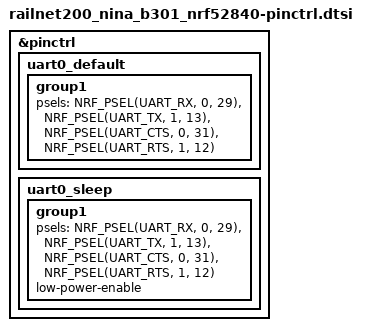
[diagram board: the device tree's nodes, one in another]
/*
 * Copyright (c) 2025 Naonext
 * SPDX-License-Identifier: Apache-2.0
 */

/*
 * NINA-B301 pin mapping on Railnet200 board (u-blox NINA-B301-00B, U22)
 *
 * The NINA-B301 is wired directly to the iMX6 CPU via its module pins.
 * UART0 of the nRF52840 inside NINA-B301 is used for HCI transport.
 *
 * NINA-B301 module pin -> nRF52840 GPIO -> signal name (Railnet200 net)
 *   Pin 23 (GPIO_23 / P0.29) -> UART_RX  -> BLE_UART_TX  (iMX6 TX → NINA RXD)
 *   Pin 22 (GPIO_22 / P1.13) -> UART_TX  -> BLE_UART_RX  (iMX6 RX ← NINA TXD)
 *   Pin 20 (GPIO_20 / P0.31) -> UART_CTS <- BLE_UART_CTS (iMX6 ball55 DCE_CTS out → NINA CTS in)
 *   Pin 21 (GPIO_21 / P1.12) -> UART_RTS -> BLE_UART_RTS (iMX6 ball58 DCE_RTS in  ← NINA RTS out)
 */

&pinctrl {
	uart0_default: uart0_default {
		group1 {
			psels = <NRF_PSEL(UART_RX,  0, 29)>,
				<NRF_PSEL(UART_TX,  1, 13)>,
				<NRF_PSEL(UART_CTS, 0, 31)>,
				<NRF_PSEL(UART_RTS, 1, 12)>;
		};
	};

	uart0_sleep: uart0_sleep {
		group1 {
			psels = <NRF_PSEL(UART_RX,  0, 29)>,
				<NRF_PSEL(UART_TX,  1, 13)>,
				<NRF_PSEL(UART_CTS, 0, 31)>,
				<NRF_PSEL(UART_RTS, 1, 12)>;
			low-power-enable;
		};
	};
};
